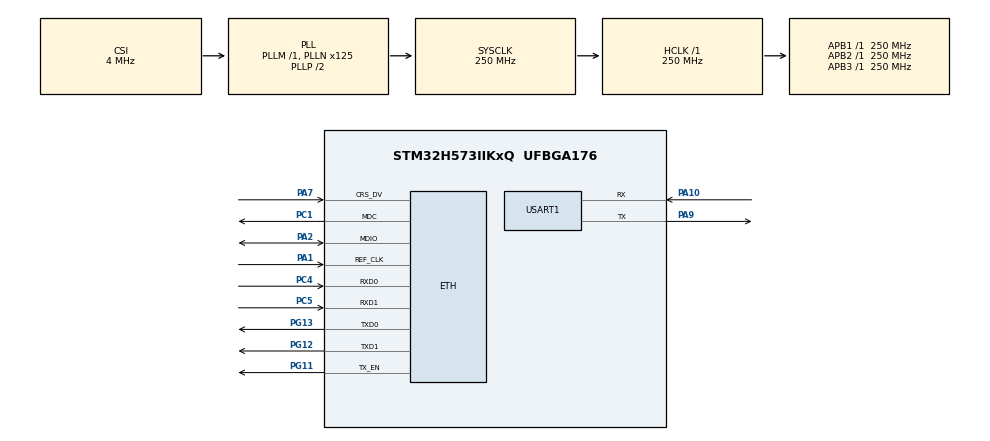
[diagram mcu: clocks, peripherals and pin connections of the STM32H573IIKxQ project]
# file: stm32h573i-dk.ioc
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BOOTPATH.BootPathName=LEGACY
BOOTPATH.UserSelectedBootPath=LEGACY
CORTEX_M33_NS.userName=CORTEX_M33
ETH.MediaInterface=HAL_ETH_RMII_MODE
Mcu.Family=STM32H5
Mcu.Name=STM32H573IIKxQ
Mcu.Package=UFBGA176
NVIC.PriorityGroup=NVIC_PRIORITYGROUP_4
PA1.Mode=RMII
PA1.Signal=ETH_REF_CLK
PA10.Mode=Asynchronous
PA10.Signal=USART1_RX
PA2.Mode=RMII
PA2.Signal=ETH_MDIO
PA7.Mode=RMII
PA7.Signal=ETH_CRS_DV
PA9.Mode=Asynchronous
PA9.Signal=USART1_TX
PC1.Mode=RMII
PC1.Signal=ETH_MDC
PC4.Mode=RMII
PC4.Signal=ETH_RXD0
PC5.Mode=RMII
PC5.Signal=ETH_RXD1
PG11.Mode=RMII
PG11.Signal=ETH_TX_EN
PG12.Mode=RMII
PG12.Signal=ETH_TXD1
PG13.Mode=RMII
PG13.Signal=ETH_TXD0
ProjectManager.HeapSize=0x10000
ProjectManager.StackSize=0x2000
ProjectManager.TargetToolchain=CMake
RCC.ADCFreq_Value=250000000
RCC.AHBFreq_Value=250000000
RCC.APB1Freq_Value=250000000
RCC.APB1TimFreq_Value=250000000
RCC.APB2Freq_Value=250000000
RCC.APB2TimFreq_Value=250000000
RCC.APB3Freq_Value=250000000
RCC.CSI_VALUE=4000000
RCC.CortexFreq_Value=250000000
RCC.EPOD_VALUE=4000000
RCC.HCLKFreq_Value=250000000
RCC.HSE_VALUE=25000000
RCC.HSI48_VALUE=48000000
RCC.HSI_VALUE=64000000
RCC.LSE_VALUE=32768
RCC.LSIRC_VALUE=32000
RCC.PLL2FRACN=0
RCC.PLL3FRACN=0
RCC.PLLFRACN=0
RCC.PLLN=125
RCC.SYSCLKFreq_VALUE=250000000
RCC.SYSCLKSource=RCC_SYSCLKSOURCE_PLLCLK
RCC.USBFreq_Value=48000000
RCC.VCOOutputFreq_Value=500000000
USART1.VirtualMode-Asynchronous=VM_ASYNC
VP_BOOTPATH_VS_BOOTPATH.Mode=BP_Activate
VP_CORTEX_M33_NS_VS_Hclk.Mode=Hclk_Mode
VP_MEMORYMAP_VS_MEMORYMAP.Mode=CurAppReg
VP_PWR_VS_LPOM.Mode=PowerOptimisation
VP_PWR_VS_SECSignals.Mode=Security/Privilege
VP_RNG_VS_RNG.Mode=RNG_Activate
board=custom

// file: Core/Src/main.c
/* USER CODE BEGIN Header */
/**
  ******************************************************************************
  * @file           : main.c
  * @brief          : Main program body
  ******************************************************************************
  * @attention
  *
  * Copyright (c) 2026 STMicroelectronics.
  * All rights reserved.
  *
  * This software is licensed under terms that can be found in the LICENSE file
  * in the root directory of this software component.
  * If no LICENSE file comes with this software, it is provided AS-IS.
  *
  ******************************************************************************
  */
/* USER CODE END Header */
#include "main.h"
#include "stm32h573xx.h"
#include "string.h"

/* USER CODE BEGIN Includes */
#include "mongoose.h"

/* USER CODE END Includes */

ETH_TxPacketConfigTypeDef TxConfig;
ETH_DMADescTypeDef  DMARxDscrTab[ETH_RX_DESC_CNT]; /* Ethernet Rx DMA Descriptors */
ETH_DMADescTypeDef  DMATxDscrTab[ETH_TX_DESC_CNT]; /* Ethernet Tx DMA Descriptors */

ETH_HandleTypeDef heth;

RNG_HandleTypeDef hrng;

UART_HandleTypeDef huart1;

void SystemClock_Config(void);
static void MX_GPIO_Init(void);
static void MX_ETH_Init(void);
static void MX_RNG_Init(void);
static void MX_USART1_UART_Init(void);

/* USER CODE BEGIN 0 */
int _write(int fd, unsigned char *buf, int len) {
  HAL_UART_Transmit(&huart1, buf, len, HAL_MAX_DELAY);
  return len;
}

/* USER CODE END 0 */

int main(void)
{

  /* MCU Configuration--------------------------------------------------------*/

  /* Reset of all peripherals, Initializes the Flash interface and the Systick. */
  HAL_Init();

  /* Configure the system clock */
  SystemClock_Config();

  /* Initialize all configured peripherals */
  MX_GPIO_Init();
  MX_ETH_Init();
  MX_RNG_Init();
  MX_USART1_UART_Init();

  /* Infinite loop */
  /* USER CODE BEGIN WHILE */
  struct mg_mgr mgr;
  mg_mgr_init(&mgr);
  mg_dash_init(&mgr);

  while (1)
  {
    mg_mgr_poll(&mgr, 0);
    mg_dash_poll(&mgr);
    /* USER CODE END WHILE */

  }
}

void SystemClock_Config(void)
{
  RCC_OscInitTypeDef RCC_OscInitStruct = {0};
  RCC_ClkInitTypeDef RCC_ClkInitStruct = {0};

  /** Configure the main internal regulator output voltage
  */
  __HAL_PWR_VOLTAGESCALING_CONFIG(PWR_REGULATOR_VOLTAGE_SCALE0);

  while(!__HAL_PWR_GET_FLAG(PWR_FLAG_VOSRDY)) {}

  /** Initializes the RCC Oscillators according to the specified parameters
  * in the RCC_OscInitTypeDef structure.
  */
  RCC_OscInitStruct.OscillatorType = RCC_OSCILLATORTYPE_HSI48|RCC_OSCILLATORTYPE_CSI;
  RCC_OscInitStruct.HSI48State = RCC_HSI48_ON;
  RCC_OscInitStruct.CSIState = RCC_CSI_ON;
  RCC_OscInitStruct.CSICalibrationValue = RCC_CSICALIBRATION_DEFAULT;
  RCC_OscInitStruct.PLL.PLLState = RCC_PLL_ON;
  RCC_OscInitStruct.PLL.PLLSource = RCC_PLL1_SOURCE_CSI;
  RCC_OscInitStruct.PLL.PLLM = 1;
  RCC_OscInitStruct.PLL.PLLN = 125;
  RCC_OscInitStruct.PLL.PLLP = 2;
  RCC_OscInitStruct.PLL.PLLQ = 2;
  RCC_OscInitStruct.PLL.PLLR = 2;
  RCC_OscInitStruct.PLL.PLLRGE = RCC_PLL1_VCIRANGE_2;
  RCC_OscInitStruct.PLL.PLLVCOSEL = RCC_PLL1_VCORANGE_WIDE;
  RCC_OscInitStruct.PLL.PLLFRACN = 0;
  if (HAL_RCC_OscConfig(&RCC_OscInitStruct) != HAL_OK)
  {
    Error_Handler();
  }

  /** Initializes the CPU, AHB and APB buses clocks
  */
  RCC_ClkInitStruct.ClockType = RCC_CLOCKTYPE_HCLK|RCC_CLOCKTYPE_SYSCLK
                              |RCC_CLOCKTYPE_PCLK1|RCC_CLOCKTYPE_PCLK2
                              |RCC_CLOCKTYPE_PCLK3;
  RCC_ClkInitStruct.SYSCLKSource = RCC_SYSCLKSOURCE_PLLCLK;
  RCC_ClkInitStruct.AHBCLKDivider = RCC_SYSCLK_DIV1;
  RCC_ClkInitStruct.APB1CLKDivider = RCC_HCLK_DIV1;
  RCC_ClkInitStruct.APB2CLKDivider = RCC_HCLK_DIV1;
  RCC_ClkInitStruct.APB3CLKDivider = RCC_HCLK_DIV1;

  if (HAL_RCC_ClockConfig(&RCC_ClkInitStruct, FLASH_LATENCY_5) != HAL_OK)
  {
    Error_Handler();
  }

  /** Configure the programming delay
  */
  __HAL_FLASH_SET_PROGRAM_DELAY(FLASH_PROGRAMMING_DELAY_2);
}

static void MX_ETH_Init(void)
{

   static uint8_t MACAddr[6];

  heth.Instance = ETH;
  MACAddr[0] = 0x00;
  MACAddr[1] = 0x80;
  MACAddr[2] = 0xE1;
  MACAddr[3] = 0x00;
  MACAddr[4] = 0x00;
  MACAddr[5] = 0x00;
  heth.Init.MACAddr = &MACAddr[0];
  heth.Init.MediaInterface = HAL_ETH_RMII_MODE;
  heth.Init.TxDesc = DMATxDscrTab;
  heth.Init.RxDesc = DMARxDscrTab;
  heth.Init.RxBuffLen = 1524;

  if (HAL_ETH_Init(&heth) != HAL_OK)
  {
    Error_Handler();
  }

  memset(&TxConfig, 0 , sizeof(ETH_TxPacketConfigTypeDef));
  TxConfig.Attributes = ETH_TX_PACKETS_FEATURES_CSUM | ETH_TX_PACKETS_FEATURES_CRCPAD;
  TxConfig.ChecksumCtrl = ETH_CHECKSUM_IPHDR_PAYLOAD_INSERT_PHDR_CALC;
  TxConfig.CRCPadCtrl = ETH_CRC_PAD_INSERT;

}

static void MX_RNG_Init(void)
{

  hrng.Instance = RNG;
  hrng.Init.ClockErrorDetection = RNG_CED_ENABLE;
  if (HAL_RNG_Init(&hrng) != HAL_OK)
  {
    Error_Handler();
  }

}

static void MX_USART1_UART_Init(void)
{

  huart1.Instance = USART1;
  huart1.Init.BaudRate = 115200;
  huart1.Init.WordLength = UART_WORDLENGTH_8B;
  huart1.Init.StopBits = UART_STOPBITS_1;
  huart1.Init.Parity = UART_PARITY_NONE;
  huart1.Init.Mode = UART_MODE_TX_RX;
  huart1.Init.HwFlowCtl = UART_HWCONTROL_NONE;
  huart1.Init.OverSampling = UART_OVERSAMPLING_16;
  huart1.Init.OneBitSampling = UART_ONE_BIT_SAMPLE_DISABLE;
  huart1.Init.ClockPrescaler = UART_PRESCALER_DIV1;
  huart1.AdvancedInit.AdvFeatureInit = UART_ADVFEATURE_NO_INIT;
  if (HAL_UART_Init(&huart1) != HAL_OK)
  {
    Error_Handler();
  }
  if (HAL_UARTEx_SetTxFifoThreshold(&huart1, UART_TXFIFO_THRESHOLD_1_8) != HAL_OK)
  {
    Error_Handler();
  }
  if (HAL_UARTEx_SetRxFifoThreshold(&huart1, UART_RXFIFO_THRESHOLD_1_8) != HAL_OK)
  {
    Error_Handler();
  }
  if (HAL_UARTEx_DisableFifoMode(&huart1) != HAL_OK)
  {
    Error_Handler();
  }

}

static void MX_GPIO_Init(void)
{

  /* GPIO Ports Clock Enable */
  __HAL_RCC_GPIOG_CLK_ENABLE();
  __HAL_RCC_GPIOA_CLK_ENABLE();
  __HAL_RCC_GPIOC_CLK_ENABLE();

}

void Error_Handler(void)
{
  __disable_irq();
  while (1)
  {
  }
}
